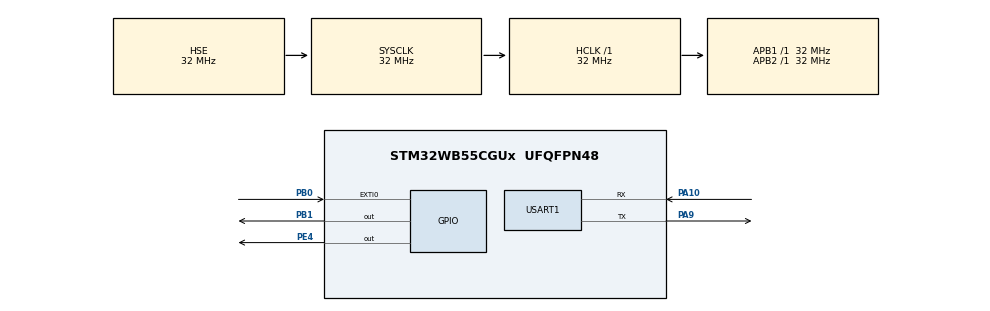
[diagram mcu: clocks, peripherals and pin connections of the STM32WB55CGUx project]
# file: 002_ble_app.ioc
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Dma.Request0=USART1_TX
Dma.USART1_TX.0.Direction=DMA_MEMORY_TO_PERIPH
Dma.USART1_TX.0.EventEnable=DISABLE
Dma.USART1_TX.0.Instance=DMA1_Channel1
Dma.USART1_TX.0.MemDataAlignment=DMA_MDATAALIGN_BYTE
Dma.USART1_TX.0.MemInc=DMA_MINC_ENABLE
Dma.USART1_TX.0.Mode=DMA_NORMAL
Dma.USART1_TX.0.PeriphDataAlignment=DMA_PDATAALIGN_BYTE
Dma.USART1_TX.0.PeriphInc=DMA_PINC_DISABLE
Dma.USART1_TX.0.Polarity=HAL_DMAMUX_REQ_GEN_RISING
Dma.USART1_TX.0.Priority=DMA_PRIORITY_LOW
Dma.USART1_TX.0.RequestNumber=1
Dma.USART1_TX.0.SignalID=NONE
Dma.USART1_TX.0.SyncEnable=DISABLE
Dma.USART1_TX.0.SyncPolarity=HAL_DMAMUX_SYNC_NO_EVENT
Dma.USART1_TX.0.SyncRequestNumber=1
Dma.USART1_TX.0.SyncSignalID=NONE
Mcu.Family=STM32WB
Mcu.Name=STM32WB55CGUx
Mcu.Package=UFQFPN48
NVIC.DMA1_Channel1_IRQn=true\:15\:0\:true\:false\:true\:false\:true\:true
NVIC.EXTI0_IRQn=true\:0\:0\:false\:false\:true\:true\:true\:true
NVIC.HSEM_IRQn=true\:0\:0\:false\:false\:true\:false\:true\:true
NVIC.IPCC_C1_RX_IRQn=true\:0\:0\:false\:false\:true\:true\:true\:true
NVIC.IPCC_C1_TX_IRQn=true\:0\:0\:false\:false\:true\:true\:true\:true
NVIC.PriorityGroup=NVIC_PRIORITYGROUP_4
NVIC.RTC_WKUP_IRQn=true\:0\:0\:false\:false\:true\:true\:true\:true
NVIC.USART1_IRQn=true\:0\:0\:false\:false\:true\:true\:true\:true
OSC_IN.Mode=HSE-External-Oscillator
OSC_IN.Signal=RCC_OSC_IN
OSC_OUT.Mode=HSE-External-Oscillator
OSC_OUT.Signal=RCC_OSC_OUT
PA10.Mode=Asynchronous
PA10.Signal=USART1_RX
PA9.Mode=Asynchronous
PA9.Signal=USART1_TX
PB0.Signal=GPXTI0
PB1.Signal=GPIO_Output
PC14-OSC32_IN.Mode=LSE-External-Oscillator
PC14-OSC32_IN.Signal=RCC_OSC32_IN
PC15-OSC32_OUT.Mode=LSE-External-Oscillator
PC15-OSC32_OUT.Signal=RCC_OSC32_OUT
PE4.Signal=GPIO_Output
ProjectManager.HeapSize=0x200
ProjectManager.StackSize=0x400
ProjectManager.TargetToolchain=STM32CubeIDE
RCC.ADCFreq_Value=128000000
RCC.AHBFreq_Value=32000000
RCC.APB1Freq_Value=32000000
RCC.APB1TimFreq_Value=32000000
RCC.APB2Freq_Value=32000000
RCC.APB2TimFreq_Value=32000000
RCC.APB3Freq_Value=16000000
RCC.CortexFreq_Value=32000000
RCC.HCLKFreq_Value=32000000
RCC.HSE_VALUE=32000000
RCC.HSI48_VALUE=48000000
RCC.HSI_VALUE=16000000
RCC.MSIClockRange=RCC_MSIRANGE_10
RCC.RFWKPClockSelection=RCC_RFWKPCLKSOURCE_LSE
RCC.RTCClockSelection=RCC_RTCCLKSOURCE_LSE
RCC.SMPSCLockSelection=RCC_SMPSCLKSOURCE_HSE
RCC.SMPSDivider=4
RCC.SYSCLKFreq_VALUE=32000000
RCC.SYSCLKSource=RCC_SYSCLKSOURCE_HSE
RCC.USBFreq_Value=128000000
RCC.VCOOutputFreq_Value=256000000
RF1.Mode=RF1_Activate
RF1.Signal=RF_RF1
STM32_WPAN.CFG_DEBUG_APP_TRACE=1
STM32_WPAN.CFG_DEBUG_BLE_TRACE=1
STM32_WPAN.CFG_DEBUG_TRACE_FULL=1
STM32_WPAN.CFG_DEBUG_TRACE_UART=hw_uart1
STM32_WPAN.CFG_HW_RESET_BY_FW=1
STM32_WPAN.CFG_HW_USART1_ENABLED=1
STM32_WPAN.CFG_LSCLK_LSE=0
STM32_WPAN.CUSTOM_P2P_SERVER=Disabled
STM32_WPAN.CUSTOM_TEMPLATE=Enabled
STM32_WPAN.INCLUDE_AD_TYPE_16_BIT_SERV_UUID_CMPLT_LIST=1
STM32_WPAN.INCLUDE_AD_TYPE_COMPLETE_LOCAL_NAME=1
STM32_WPAN.INCLUDE_AD_TYPE_MANUFACTURER_SPECIFIC_DATA=1
STM32_WPAN.INCLUDE_AD_TYPE_TX_POWER_LEVEL=1
STM32_WPAN.NUMBER_OF_SERVICES=1
STM32_WPAN.PAIRING_PARAMETERS=ON
STM32_WPAN.SERVICE1_CHAR1_GATT_NOTIFY_READ_REQ_AND_WAIT_FOR_APPL_RESP=\ 
STM32_WPAN.SERVICE1_CHAR1_GATT_NOTIFY_WRITE_REQ_AND_WAIT_FOR_APPL_RESP=\ 
STM32_WPAN.SERVICE1_CHAR1_LENGTH_CHARACTERISTIC=CHAR_VALUE_LEN_VARIABLE
STM32_WPAN.SERVICE1_CHAR1_LONG_NAME=My_LED_Char
STM32_WPAN.SERVICE1_CHAR1_PROP_READ=CHAR_PROP_READ
STM32_WPAN.SERVICE1_CHAR1_PROP_WRITE_WITHOUT_RESP=CHAR_PROP_WRITE_WITHOUT_RESP
STM32_WPAN.SERVICE1_CHAR1_SHORT_NAME=LED_C
STM32_WPAN.SERVICE1_CHAR1_UUID=FE 41
STM32_WPAN.SERVICE1_CHAR1_VALUE_LENGTH=2
STM32_WPAN.SERVICE1_CHAR2_GATT_NOTIFY_READ_REQ_AND_WAIT_FOR_APPL_RESP=\ 
STM32_WPAN.SERVICE1_CHAR2_GATT_NOTIFY_WRITE_REQ_AND_WAIT_FOR_APPL_RESP=\ 
STM32_WPAN.SERVICE1_CHAR2_LENGTH_CHARACTERISTIC=CHAR_VALUE_LEN_VARIABLE
STM32_WPAN.SERVICE1_CHAR2_LONG_NAME=My_Switch_Char
STM32_WPAN.SERVICE1_CHAR2_PROP_NOTIFY=CHAR_PROP_NOTIFY
STM32_WPAN.SERVICE1_CHAR2_SHORT_NAME=SWITCH_C
STM32_WPAN.SERVICE1_CHAR2_UUID=FE 42
STM32_WPAN.SERVICE1_CHAR2_VALUE_LENGTH=2
STM32_WPAN.SERVICE1_LONG_NAME=My_P2P_Server
STM32_WPAN.SERVICE1_NUMBER_OF_CHARACTERISTICS=2
STM32_WPAN.SERVICE1_SHORT_NAME=P2PS
STM32_WPAN.SERVICE1_UUID=FE 40
USART1.VirtualMode-Asynchronous=VM_ASYNC
VP_HSEM_VS_HSEM.Mode=HSEM_Activate
VP_IPCC_VS_IPCC.Mode=IPCC_Activate
VP_MEMORYMAP_VS_MEMORYMAP.Mode=CurAppReg
VP_RTC_VS_RTC_Activate.Mode=RTC_Enabled
VP_RTC_VS_RTC_WakeUp_intern.Mode=WakeUp
VP_SEQUENCER_VS_SEQUENCER.Mode=SEQUENCER_Enabled
VP_STM32_WPAN_VS_BLE_HOST.Mode=STM32_WPAN_Enabled
VP_TINY_LPM_VS_TINY_LPM.Mode=TINY_LPM_Enabled
board=custom

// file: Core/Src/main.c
/* USER CODE BEGIN Header */
/**
  ******************************************************************************
  * @file           : main.c
  * @brief          : Main program body
  ******************************************************************************
  * @attention
  *
  * Copyright (c) 2025 STMicroelectronics.
  * All rights reserved.
  *
  * This software is licensed under terms that can be found in the LICENSE file
  * in the root directory of this software component.
  * If no LICENSE file comes with this software, it is provided AS-IS.
  *
  ******************************************************************************
  ******************************************************************************
  * sw1: PB0
  * LED: PB1
  */
/* USER CODE END Header */
#include "main.h"

IPCC_HandleTypeDef hipcc;

RTC_HandleTypeDef hrtc;

UART_HandleTypeDef huart1;
DMA_HandleTypeDef hdma_usart1_tx;

void SystemClock_Config(void);
void PeriphCommonClock_Config(void);
static void MX_GPIO_Init(void);
static void MX_DMA_Init(void);
static void MX_IPCC_Init(void);
static void MX_RTC_Init(void);
void MX_USART1_UART_Init(void);
static void MX_RF_Init(void);

int main(void)
{

  /* MCU Configuration--------------------------------------------------------*/

  /* Reset of all peripherals, Initializes the Flash interface and the Systick. */
  HAL_Init();
  /* Config code for STM32_WPAN (HSE Tuning must be done before system clock configuration) */
  MX_APPE_Config();

  /* Configure the system clock */
  SystemClock_Config();

  /* Configure the peripherals common clocks */
  PeriphCommonClock_Config();

  /* IPCC initialisation */
  MX_IPCC_Init();

  /* Initialize all configured peripherals */
  MX_GPIO_Init();
  MX_DMA_Init();
  MX_RTC_Init();
  MX_USART1_UART_Init();
  MX_RF_Init();
  /* USER CODE BEGIN 2 */
  HAL_NVIC_SetPriority(EXTI0_IRQn, 0, 0);
  HAL_NVIC_EnableIRQ(EXTI0_IRQn);

  HAL_GPIO_WritePin(GPIOE,GPIO_PIN_4,GPIO_PIN_SET);
  /* USER CODE END 2 */

  /* Init code for STM32_WPAN */
  MX_APPE_Init();

  /* Infinite loop */
  while (1)
  {
    MX_APPE_Process();

  }
}

void SystemClock_Config(void)
{
  RCC_OscInitTypeDef RCC_OscInitStruct = {0};
  RCC_ClkInitTypeDef RCC_ClkInitStruct = {0};

  /** Configure LSE Drive Capability
  */
  HAL_PWR_EnableBkUpAccess();
  __HAL_RCC_LSEDRIVE_CONFIG(RCC_LSEDRIVE_MEDIUMHIGH);

  /** Configure the main internal regulator output voltage
  */
  __HAL_PWR_VOLTAGESCALING_CONFIG(PWR_REGULATOR_VOLTAGE_SCALE1);

  /** Initializes the RCC Oscillators according to the specified parameters
  * in the RCC_OscInitTypeDef structure.
  */
  RCC_OscInitStruct.OscillatorType = RCC_OSCILLATORTYPE_HSI|RCC_OSCILLATORTYPE_HSE
                              |RCC_OSCILLATORTYPE_LSE;
  RCC_OscInitStruct.HSEState = RCC_HSE_ON;
  RCC_OscInitStruct.LSEState = RCC_LSE_ON;
  RCC_OscInitStruct.HSIState = RCC_HSI_ON;
  RCC_OscInitStruct.HSICalibrationValue = RCC_HSICALIBRATION_DEFAULT;
  RCC_OscInitStruct.PLL.PLLState = RCC_PLL_NONE;
  if (HAL_RCC_OscConfig(&RCC_OscInitStruct) != HAL_OK)
  {
    Error_Handler();
  }

  /** Configure the SYSCLKSource, HCLK, PCLK1 and PCLK2 clocks dividers
  */
  RCC_ClkInitStruct.ClockType = RCC_CLOCKTYPE_HCLK4|RCC_CLOCKTYPE_HCLK2
                              |RCC_CLOCKTYPE_HCLK|RCC_CLOCKTYPE_SYSCLK
                              |RCC_CLOCKTYPE_PCLK1|RCC_CLOCKTYPE_PCLK2;
  RCC_ClkInitStruct.SYSCLKSource = RCC_SYSCLKSOURCE_HSE;
  RCC_ClkInitStruct.AHBCLKDivider = RCC_SYSCLK_DIV1;
  RCC_ClkInitStruct.APB1CLKDivider = RCC_HCLK_DIV1;
  RCC_ClkInitStruct.APB2CLKDivider = RCC_HCLK_DIV1;
  RCC_ClkInitStruct.AHBCLK2Divider = RCC_SYSCLK_DIV1;
  RCC_ClkInitStruct.AHBCLK4Divider = RCC_SYSCLK_DIV1;

  if (HAL_RCC_ClockConfig(&RCC_ClkInitStruct, FLASH_LATENCY_1) != HAL_OK)
  {
    Error_Handler();
  }
}

void PeriphCommonClock_Config(void)
{
  RCC_PeriphCLKInitTypeDef PeriphClkInitStruct = {0};

  /** Initializes the peripherals clock
  */
  PeriphClkInitStruct.PeriphClockSelection = RCC_PERIPHCLK_SMPS|RCC_PERIPHCLK_RFWAKEUP;
  PeriphClkInitStruct.RFWakeUpClockSelection = RCC_RFWKPCLKSOURCE_LSE;
  PeriphClkInitStruct.SmpsClockSelection = RCC_SMPSCLKSOURCE_HSE;
  PeriphClkInitStruct.SmpsDivSelection = RCC_SMPSCLKDIV_RANGE1;

  if (HAL_RCCEx_PeriphCLKConfig(&PeriphClkInitStruct) != HAL_OK)
  {
    Error_Handler();
  }
}

static void MX_IPCC_Init(void)
{

  hipcc.Instance = IPCC;
  if (HAL_IPCC_Init(&hipcc) != HAL_OK)
  {
    Error_Handler();
  }

}

static void MX_RF_Init(void)
{

}

static void MX_RTC_Init(void)
{

  /** Initialize RTC Only
  */
  hrtc.Instance = RTC;
  hrtc.Init.HourFormat = RTC_HOURFORMAT_24;
  hrtc.Init.AsynchPrediv = CFG_RTC_ASYNCH_PRESCALER;
  hrtc.Init.SynchPrediv = CFG_RTC_SYNCH_PRESCALER;
  hrtc.Init.OutPut = RTC_OUTPUT_DISABLE;
  hrtc.Init.OutPutPolarity = RTC_OUTPUT_POLARITY_HIGH;
  hrtc.Init.OutPutType = RTC_OUTPUT_TYPE_OPENDRAIN;
  hrtc.Init.OutPutRemap = RTC_OUTPUT_REMAP_NONE;
  if (HAL_RTC_Init(&hrtc) != HAL_OK)
  {
    Error_Handler();
  }

  /** Enable the WakeUp
  */
  if (HAL_RTCEx_SetWakeUpTimer_IT(&hrtc, 0, RTC_WAKEUPCLOCK_RTCCLK_DIV16) != HAL_OK)
  {
    Error_Handler();
  }

}

void MX_USART1_UART_Init(void)
{

  huart1.Instance = USART1;
  huart1.Init.BaudRate = 115200;
  huart1.Init.WordLength = UART_WORDLENGTH_8B;
  huart1.Init.StopBits = UART_STOPBITS_1;
  huart1.Init.Parity = UART_PARITY_NONE;
  huart1.Init.Mode = UART_MODE_TX_RX;
  huart1.Init.HwFlowCtl = UART_HWCONTROL_NONE;
  huart1.Init.OverSampling = UART_OVERSAMPLING_8;
  huart1.Init.OneBitSampling = UART_ONE_BIT_SAMPLE_DISABLE;
  huart1.Init.ClockPrescaler = UART_PRESCALER_DIV1;
  huart1.AdvancedInit.AdvFeatureInit = UART_ADVFEATURE_NO_INIT;
  if (HAL_UART_Init(&huart1) != HAL_OK)
  {
    Error_Handler();
  }
  if (HAL_UARTEx_SetTxFifoThreshold(&huart1, UART_TXFIFO_THRESHOLD_1_8) != HAL_OK)
  {
    Error_Handler();
  }
  if (HAL_UARTEx_SetRxFifoThreshold(&huart1, UART_RXFIFO_THRESHOLD_1_8) != HAL_OK)
  {
    Error_Handler();
  }
  if (HAL_UARTEx_DisableFifoMode(&huart1) != HAL_OK)
  {
    Error_Handler();
  }

}

static void MX_DMA_Init(void)
{

  /* DMA controller clock enable */
  __HAL_RCC_DMAMUX1_CLK_ENABLE();
  __HAL_RCC_DMA1_CLK_ENABLE();

  /* DMA interrupt init */
  /* DMA1_Channel1_IRQn interrupt configuration */
  HAL_NVIC_SetPriority(DMA1_Channel1_IRQn, 15, 0);
  HAL_NVIC_EnableIRQ(DMA1_Channel1_IRQn);

}

static void MX_GPIO_Init(void)
{
  GPIO_InitTypeDef GPIO_InitStruct = {0};

  /* GPIO Ports Clock Enable */
  __HAL_RCC_GPIOC_CLK_ENABLE();
  __HAL_RCC_GPIOA_CLK_ENABLE();
  __HAL_RCC_GPIOB_CLK_ENABLE();
  __HAL_RCC_GPIOE_CLK_ENABLE();

  /*Configure GPIO pin Output Level */
  HAL_GPIO_WritePin(GPIOB, GPIO_PIN_1, GPIO_PIN_RESET);

  /*Configure GPIO pin Output Level */
  HAL_GPIO_WritePin(GPIOE, GPIO_PIN_4, GPIO_PIN_RESET);

  /*Configure GPIO pin : PB0 */
  GPIO_InitStruct.Pin = GPIO_PIN_0;
  GPIO_InitStruct.Mode = GPIO_MODE_IT_RISING;
  GPIO_InitStruct.Pull = GPIO_NOPULL;
  HAL_GPIO_Init(GPIOB, &GPIO_InitStruct);

  /*Configure GPIO pin : PB1 */
  GPIO_InitStruct.Pin = GPIO_PIN_1;
  GPIO_InitStruct.Mode = GPIO_MODE_OUTPUT_PP;
  GPIO_InitStruct.Pull = GPIO_NOPULL;
  GPIO_InitStruct.Speed = GPIO_SPEED_FREQ_LOW;
  HAL_GPIO_Init(GPIOB, &GPIO_InitStruct);

  /*Configure GPIO pin : PE4 */
  GPIO_InitStruct.Pin = GPIO_PIN_4;
  GPIO_InitStruct.Mode = GPIO_MODE_OUTPUT_PP;
  GPIO_InitStruct.Pull = GPIO_NOPULL;
  GPIO_InitStruct.Speed = GPIO_SPEED_FREQ_LOW;
  HAL_GPIO_Init(GPIOE, &GPIO_InitStruct);

  /* EXTI interrupt init*/
  HAL_NVIC_SetPriority(EXTI0_IRQn, 0, 0);
  HAL_NVIC_EnableIRQ(EXTI0_IRQn);

}

/* USER CODE BEGIN 4 */
// Add this to your main.c or interrupt handlers file

/* USER CODE END 4 */

void Error_Handler(void)
{
  __disable_irq();
  while (1)
  {
  }
}
